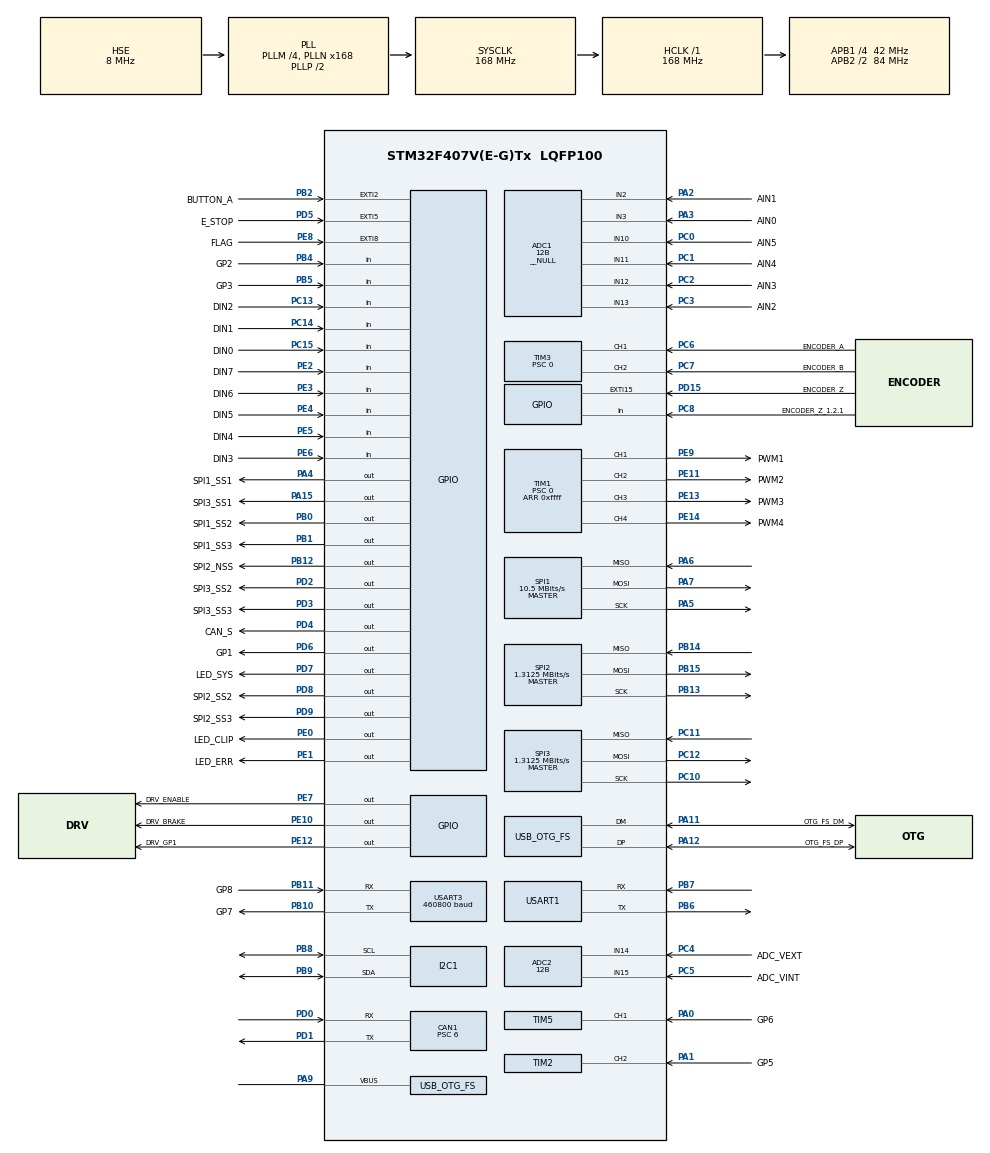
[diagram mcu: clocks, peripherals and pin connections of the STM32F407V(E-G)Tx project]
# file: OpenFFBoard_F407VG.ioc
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ADC1.Channel-1\#ChannelRegularConversion=ADC_CHANNEL_3
ADC1.Channel-2\#ChannelRegularConversion=ADC_CHANNEL_2
ADC1.Channel-3\#ChannelRegularConversion=ADC_CHANNEL_13
ADC1.Channel-4\#ChannelRegularConversion=ADC_CHANNEL_12
ADC1.Channel-5\#ChannelRegularConversion=ADC_CHANNEL_11
ADC1.Channel-6\#ChannelRegularConversion=ADC_CHANNEL_10
ADC1.Channel-7\#ChannelRegularConversion=ADC_CHANNEL_TEMPSENSOR
ADC1.Channel-9\#ChannelRegularConversion=ADC_CHANNEL_VREFINT
ADC1.Channel-IN10=ADC_CHANNEL_10
ADC1.Channel-IN11=ADC_CHANNEL_11
ADC1.Channel-IN12=ADC_CHANNEL_12
ADC1.Channel-IN13=ADC_CHANNEL_13
ADC1.ClockPrescaler=ADC_CLOCK_SYNC_PCLK_DIV4
ADC1.ContinuousConvMode=DISABLE
ADC1.DMAContinuousRequests=ENABLE
ADC1.DataAlign=ADC_DATAALIGN_RIGHT
ADC1.DiscontinuousConvMode=DISABLE
ADC1.EOCSelection=ADC_EOC_SINGLE_CONV
ADC1.EnableAnalogWatchDog=false
ADC1.ExternalTrigConv=ADC_EXTERNALTRIGCONV_T4_CC4
ADC1.ExternalTrigConvEdge=ADC_EXTERNALTRIGCONVEDGE_RISING
ADC1.InjNumberOfConversion=0
ADC1.Mode=__NULL
ADC1.NbrOfConversion=8
ADC1.Rank-1\#ChannelRegularConversion=1
ADC1.Rank-2\#ChannelRegularConversion=2
ADC1.Rank-3\#ChannelRegularConversion=3
ADC1.Rank-4\#ChannelRegularConversion=4
ADC1.Rank-5\#ChannelRegularConversion=5
ADC1.Rank-6\#ChannelRegularConversion=6
ADC1.Rank-7\#ChannelRegularConversion=7
ADC1.Rank-9\#ChannelRegularConversion=8
ADC1.Resolution=ADC_RESOLUTION_12B
ADC1.SamplingTime-1\#ChannelRegularConversion=ADC_SAMPLETIME_84CYCLES
ADC1.SamplingTime-2\#ChannelRegularConversion=ADC_SAMPLETIME_84CYCLES
ADC1.SamplingTime-3\#ChannelRegularConversion=ADC_SAMPLETIME_84CYCLES
ADC1.SamplingTime-4\#ChannelRegularConversion=ADC_SAMPLETIME_84CYCLES
ADC1.SamplingTime-5\#ChannelRegularConversion=ADC_SAMPLETIME_84CYCLES
ADC1.SamplingTime-6\#ChannelRegularConversion=ADC_SAMPLETIME_84CYCLES
ADC1.SamplingTime-7\#ChannelRegularConversion=ADC_SAMPLETIME_56CYCLES
ADC1.SamplingTime-9\#ChannelRegularConversion=ADC_SAMPLETIME_56CYCLES
ADC1.master=1
ADC2.Channel-0\#ChannelRegularConversion=ADC_CHANNEL_14
ADC2.Channel-1\#ChannelRegularConversion=ADC_CHANNEL_15
ADC2.ClockPrescaler=ADC_CLOCK_SYNC_PCLK_DIV4
ADC2.ContinuousConvMode=DISABLE
ADC2.DMAContinuousRequests=ENABLE
ADC2.DataAlign=ADC_DATAALIGN_RIGHT
ADC2.DiscontinuousConvMode=DISABLE
ADC2.EOCSelection=ADC_EOC_SINGLE_CONV
ADC2.EnableAnalogWatchDog=false
ADC2.ExternalTrigConv=ADC_EXTERNALTRIGCONV_T4_CC4
ADC2.ExternalTrigConvEdge=ADC_EXTERNALTRIGCONVEDGE_RISINGFALLING
ADC2.InjNumberOfConversion=0
ADC2.Mode=__NULL
ADC2.NbrOfConversion=2
ADC2.Rank-0\#ChannelRegularConversion=1
ADC2.Rank-1\#ChannelRegularConversion=2
ADC2.Resolution=ADC_RESOLUTION_12B
ADC2.SamplingTime-0\#ChannelRegularConversion=ADC_SAMPLETIME_84CYCLES
ADC2.SamplingTime-1\#ChannelRegularConversion=ADC_SAMPLETIME_84CYCLES
ADC2.ScanConvMode=ENABLE
CAN1.ABOM=DISABLE
CAN1.AWUM=DISABLE
CAN1.BS1=CAN_BS1_11TQ
CAN1.BS2=CAN_BS2_2TQ
CAN1.CalculateBaudRate=500000
CAN1.CalculateTimeBit=2000
CAN1.CalculateTimeQuantum=142.85714285714286
CAN1.Mode=CAN_MODE_NORMAL
CAN1.NART=ENABLE
CAN1.Prescaler=6
CAN1.RFLM=DISABLE
CAN1.SJW=CAN_SJW_1TQ
CAN1.TTCM=DISABLE
CAN1.TXFP=DISABLE
Dma.ADC1.0.Direction=DMA_PERIPH_TO_MEMORY
Dma.ADC1.0.FIFOMode=DMA_FIFOMODE_DISABLE
Dma.ADC1.0.Instance=DMA2_Stream4
Dma.ADC1.0.MemDataAlignment=DMA_MDATAALIGN_WORD
Dma.ADC1.0.MemInc=DMA_MINC_ENABLE
Dma.ADC1.0.Mode=DMA_CIRCULAR
Dma.ADC1.0.PeriphDataAlignment=DMA_PDATAALIGN_WORD
Dma.ADC1.0.PeriphInc=DMA_PINC_DISABLE
Dma.ADC1.0.Priority=DMA_PRIORITY_LOW
Dma.ADC2.1.Direction=DMA_PERIPH_TO_MEMORY
Dma.ADC2.1.FIFOMode=DMA_FIFOMODE_DISABLE
Dma.ADC2.1.Instance=DMA2_Stream2
Dma.ADC2.1.MemDataAlignment=DMA_MDATAALIGN_WORD
Dma.ADC2.1.MemInc=DMA_MINC_ENABLE
Dma.ADC2.1.Mode=DMA_CIRCULAR
Dma.ADC2.1.PeriphDataAlignment=DMA_PDATAALIGN_WORD
Dma.ADC2.1.PeriphInc=DMA_PINC_DISABLE
Dma.ADC2.1.Priority=DMA_PRIORITY_LOW
Dma.Request0=ADC1
Dma.Request1=ADC2
Dma.Request2=SPI1_RX
Dma.Request3=SPI1_TX
Dma.Request4=SPI3_RX
Dma.Request5=SPI3_TX
Dma.Request6=SPI2_RX
Dma.Request7=SPI2_TX
Dma.SPI1_RX.2.Direction=DMA_PERIPH_TO_MEMORY
Dma.SPI1_RX.2.FIFOMode=DMA_FIFOMODE_DISABLE
Dma.SPI1_RX.2.Instance=DMA2_Stream0
Dma.SPI1_RX.2.MemDataAlignment=DMA_MDATAALIGN_BYTE
Dma.SPI1_RX.2.MemInc=DMA_MINC_ENABLE
Dma.SPI1_RX.2.Mode=DMA_NORMAL
Dma.SPI1_RX.2.PeriphDataAlignment=DMA_PDATAALIGN_BYTE
Dma.SPI1_RX.2.PeriphInc=DMA_PINC_DISABLE
Dma.SPI1_RX.2.Priority=DMA_PRIORITY_MEDIUM
Dma.SPI1_TX.3.Direction=DMA_MEMORY_TO_PERIPH
Dma.SPI1_TX.3.FIFOMode=DMA_FIFOMODE_DISABLE
Dma.SPI1_TX.3.Instance=DMA2_Stream3
Dma.SPI1_TX.3.MemDataAlignment=DMA_MDATAALIGN_BYTE
Dma.SPI1_TX.3.MemInc=DMA_MINC_ENABLE
Dma.SPI1_TX.3.Mode=DMA_NORMAL
Dma.SPI1_TX.3.PeriphDataAlignment=DMA_PDATAALIGN_BYTE
Dma.SPI1_TX.3.PeriphInc=DMA_PINC_DISABLE
Dma.SPI1_TX.3.Priority=DMA_PRIORITY_MEDIUM
Dma.SPI2_RX.6.Direction=DMA_PERIPH_TO_MEMORY
Dma.SPI2_RX.6.FIFOMode=DMA_FIFOMODE_DISABLE
Dma.SPI2_RX.6.Instance=DMA1_Stream3
Dma.SPI2_RX.6.MemDataAlignment=DMA_MDATAALIGN_BYTE
Dma.SPI2_RX.6.MemInc=DMA_MINC_ENABLE
Dma.SPI2_RX.6.Mode=DMA_NORMAL
Dma.SPI2_RX.6.PeriphDataAlignment=DMA_PDATAALIGN_BYTE
Dma.SPI2_RX.6.PeriphInc=DMA_PINC_DISABLE
Dma.SPI2_RX.6.Priority=DMA_PRIORITY_LOW
Dma.SPI2_TX.7.Direction=DMA_MEMORY_TO_PERIPH
Dma.SPI2_TX.7.FIFOMode=DMA_FIFOMODE_DISABLE
Dma.SPI2_TX.7.Instance=DMA1_Stream4
Dma.SPI2_TX.7.MemDataAlignment=DMA_MDATAALIGN_BYTE
Dma.SPI2_TX.7.MemInc=DMA_MINC_ENABLE
Dma.SPI2_TX.7.Mode=DMA_NORMAL
Dma.SPI2_TX.7.PeriphDataAlignment=DMA_PDATAALIGN_BYTE
Dma.SPI2_TX.7.PeriphInc=DMA_PINC_DISABLE
Dma.SPI2_TX.7.Priority=DMA_PRIORITY_LOW
Dma.SPI3_RX.4.Direction=DMA_PERIPH_TO_MEMORY
Dma.SPI3_RX.4.FIFOMode=DMA_FIFOMODE_DISABLE
Dma.SPI3_RX.4.Instance=DMA1_Stream2
Dma.SPI3_RX.4.MemDataAlignment=DMA_MDATAALIGN_BYTE
Dma.SPI3_RX.4.MemInc=DMA_MINC_ENABLE
Dma.SPI3_RX.4.Mode=DMA_NORMAL
Dma.SPI3_RX.4.PeriphDataAlignment=DMA_PDATAALIGN_BYTE
Dma.SPI3_RX.4.PeriphInc=DMA_PINC_DISABLE
Dma.SPI3_RX.4.Priority=DMA_PRIORITY_MEDIUM
Dma.SPI3_TX.5.Direction=DMA_MEMORY_TO_PERIPH
Dma.SPI3_TX.5.FIFOMode=DMA_FIFOMODE_DISABLE
Dma.SPI3_TX.5.Instance=DMA1_Stream5
Dma.SPI3_TX.5.MemDataAlignment=DMA_MDATAALIGN_BYTE
Dma.SPI3_TX.5.MemInc=DMA_MINC_ENABLE
Dma.SPI3_TX.5.Mode=DMA_NORMAL
Dma.SPI3_TX.5.PeriphDataAlignment=DMA_PDATAALIGN_BYTE
Dma.SPI3_TX.5.PeriphInc=DMA_PINC_DISABLE
Dma.SPI3_TX.5.Priority=DMA_PRIORITY_MEDIUM
FREERTOS.HEAP_NUMBER=4
FREERTOS.Tasks01=defaultTask,16,512,StartDefaultTask,As weak,NULL,Dynamic,NULL,NULL
FREERTOS.configCHECK_FOR_STACK_OVERFLOW=2
FREERTOS.configENABLE_FPU=1
FREERTOS.configGENERATE_RUN_TIME_STATS=0
FREERTOS.configMINIMAL_STACK_SIZE=64
FREERTOS.configRECORD_STACK_HIGH_ADDRESS=1
FREERTOS.configTIMER_TASK_STACK_DEPTH=128
FREERTOS.configTOTAL_HEAP_SIZE=0xffff
FREERTOS.configUSE_IDLE_HOOK=1
FREERTOS.configUSE_MALLOC_FAILED_HOOK=1
FREERTOS.configUSE_NEWLIB_REENTRANT=1
FREERTOS.configUSE_STATS_FORMATTING_FUNCTIONS=0
FREERTOS.configUSE_TRACE_FACILITY=1
IWDG.Prescaler=IWDG_PRESCALER_16
Mcu.Family=STM32F4
Mcu.Name=STM32F407V(E-G)Tx
Mcu.Package=LQFP100
NVIC.CAN1_RX0_IRQn=true\:9\:0\:true\:false\:true\:true\:true\:true\:true
NVIC.CAN1_TX_IRQn=true\:10\:0\:true\:false\:true\:true\:true\:true\:true
NVIC.DMA1_Stream2_IRQn=true\:5\:0\:false\:false\:true\:true\:false\:true\:true
NVIC.DMA1_Stream3_IRQn=true\:9\:0\:true\:false\:true\:true\:false\:true\:true
NVIC.DMA1_Stream4_IRQn=true\:9\:0\:true\:false\:true\:true\:false\:true\:true
NVIC.DMA1_Stream5_IRQn=true\:5\:0\:true\:false\:true\:true\:false\:true\:true
NVIC.DMA2_Stream0_IRQn=true\:6\:0\:true\:true\:true\:1\:true\:false\:true\:true
NVIC.DMA2_Stream2_IRQn=true\:10\:0\:true\:false\:true\:true\:false\:true\:true
NVIC.DMA2_Stream3_IRQn=true\:6\:0\:true\:false\:true\:true\:false\:true\:true
NVIC.DMA2_Stream4_IRQn=true\:10\:0\:true\:false\:true\:true\:false\:true\:true
NVIC.EXTI15_10_IRQn=true\:13\:0\:true\:false\:true\:true\:true\:true\:true
NVIC.EXTI2_IRQn=true\:6\:0\:true\:false\:true\:true\:true\:true\:true
NVIC.EXTI9_5_IRQn=true\:13\:0\:true\:false\:true\:true\:true\:true\:true
NVIC.I2C1_ER_IRQn=true\:8\:0\:true\:false\:true\:true\:true\:true\:true
NVIC.I2C1_EV_IRQn=true\:8\:0\:true\:false\:true\:true\:true\:true\:true
NVIC.OTG_FS_IRQn=true\:14\:0\:true\:false\:true\:true\:true\:false\:true
NVIC.PriorityGroup=NVIC_PRIORITYGROUP_4
NVIC.SPI1_IRQn=true\:6\:0\:true\:false\:true\:true\:true\:true\:true
NVIC.SPI2_IRQn=true\:9\:0\:true\:false\:true\:true\:true\:true\:true
NVIC.SPI3_IRQn=true\:8\:0\:true\:false\:true\:true\:true\:true\:true
NVIC.TIM1_BRK_TIM9_IRQn=true\:6\:0\:true\:false\:true\:true\:true\:true\:true
NVIC.TIM2_IRQn=true\:7\:0\:true\:false\:true\:true\:true\:true\:true
NVIC.TIM3_IRQn=true\:6\:0\:true\:true\:true\:2\:true\:true\:true\:true
NVIC.TIM5_IRQn=true\:6\:0\:true\:false\:true\:true\:true\:true\:true
NVIC.TIM6_DAC_IRQn=true\:11\:0\:true\:false\:true\:true\:true\:true\:true
NVIC.TIM7_IRQn=true\:4\:0\:true\:false\:true\:false\:false\:true\:true
NVIC.TIM8_UP_TIM13_IRQn=true\:12\:0\:true\:false\:true\:false\:true\:true\:true
NVIC.TimeBase=TIM7_IRQn
NVIC.TimeBaseIP=TIM7
NVIC.USART1_IRQn=true\:7\:0\:true\:false\:true\:true\:true\:true\:true
NVIC.USART3_IRQn=true\:7\:0\:true\:false\:true\:true\:true\:true\:true
PA0-WKUP.GPIO_Label=GP6
PA0-WKUP.Signal=S_TIM5_CH1
PA1.GPIO_Label=GP5
PA1.Signal=S_TIM2_CH2
PA11.GPIO_Label=OTG_FS_DM
PA11.Mode=Device_Only
PA11.Signal=USB_OTG_FS_DM
PA12.GPIO_Label=OTG_FS_DP
PA12.Mode=Device_Only
PA12.Signal=USB_OTG_FS_DP
PA13.GPIO_Label=SWDIO
PA13.Mode=Trace_Asynchronous_SW
PA13.Signal=SYS_JTMS-SWDIO
PA14.GPIO_Label=SWCLK
PA14.Mode=Trace_Asynchronous_SW
PA14.Signal=SYS_JTCK-SWCLK
PA15.GPIO_Label=SPI3_SS1
PA15.GPIO_Speed=GPIO_SPEED_FREQ_HIGH
PA15.Signal=GPIO_Output
PA2.GPIO_Label=AIN1
PA2.Signal=ADCx_IN2
PA3.GPIO_Label=AIN0
PA3.Signal=ADCx_IN3
PA4.GPIO_Label=SPI1_SS1
PA4.GPIO_Speed=GPIO_SPEED_FREQ_VERY_HIGH
PA4.PinState=GPIO_PIN_SET
PA4.Signal=GPIO_Output
PA5.Mode=Full_Duplex_Master
PA5.Signal=SPI1_SCK
PA6.GPIO_PuPd=GPIO_NOPULL
PA6.Mode=Full_Duplex_Master
PA6.Signal=SPI1_MISO
PA7.Mode=Full_Duplex_Master
PA7.Signal=SPI1_MOSI
PA9.Mode=Activate_VBUS
PA9.Signal=USB_OTG_FS_VBUS
PB0.GPIO_Label=SPI1_SS2
PB0.GPIO_Speed=GPIO_SPEED_FREQ_HIGH
PB0.Signal=GPIO_Output
PB1.GPIO_Label=SPI1_SS3
PB1.GPIO_Speed=GPIO_SPEED_FREQ_HIGH
PB1.Signal=GPIO_Output
PB10.GPIO_Label=GP7
PB10.Mode=Asynchronous
PB10.Signal=USART3_TX
PB11.GPIO_Label=GP8
PB11.Mode=Asynchronous
PB11.Signal=USART3_RX
PB12.GPIO_Label=SPI2_NSS
PB12.GPIO_Speed=GPIO_SPEED_FREQ_HIGH
PB12.Signal=GPIO_Output
PB13.Mode=Full_Duplex_Master
PB13.Signal=SPI2_SCK
PB14.Mode=Full_Duplex_Master
PB14.Signal=SPI2_MISO
PB15.Mode=Full_Duplex_Master
PB15.Signal=SPI2_MOSI
PB2.GPIO_Label=BUTTON_A
PB2.GPIO_PuPd=GPIO_PULLDOWN
PB2.Signal=GPXTI2
PB3.GPIO_Label=GP4
PB3.Mode=Trace_Asynchronous_SW
PB3.Signal=SYS_JTDO-SWO
PB4.GPIO_Label=GP2
PB4.Signal=GPIO_Input
PB5.GPIO_Label=GP3
PB5.Signal=GPIO_Input
PB6.Mode=Asynchronous
PB6.Signal=USART1_TX
PB7.Mode=Asynchronous
PB7.Signal=USART1_RX
PB8.GPIO_Pu=GPIO_PULLUP
PB8.Mode=I2C
PB8.Signal=I2C1_SCL
PB9.GPIO_Pu=GPIO_PULLUP
PB9.Mode=I2C
PB9.Signal=I2C1_SDA
PC0.GPIO_Label=AIN5
PC0.Signal=ADCx_IN10
PC1.GPIO_Label=AIN4
PC1.Signal=ADCx_IN11
PC10.Mode=Full_Duplex_Master
PC10.Signal=SPI3_SCK
PC11.Mode=Full_Duplex_Master
PC11.Signal=SPI3_MISO
PC12.Mode=Full_Duplex_Master
PC12.Signal=SPI3_MOSI
PC13-ANTI_TAMP.GPIO_Label=DIN2
PC13-ANTI_TAMP.GPIO_PuPd=GPIO_PULLUP
PC13-ANTI_TAMP.Signal=GPIO_Input
PC14-OSC32_IN.GPIO_Label=DIN1
PC14-OSC32_IN.GPIO_PuPd=GPIO_PULLUP
PC14-OSC32_IN.Signal=GPIO_Input
PC15-OSC32_OUT.GPIO_Label=DIN0
PC15-OSC32_OUT.GPIO_PuPd=GPIO_PULLUP
PC15-OSC32_OUT.Signal=GPIO_Input
PC2.GPIO_Label=AIN3
PC2.Signal=ADCx_IN12
PC3.GPIO_Label=AIN2
PC3.Signal=ADCx_IN13
PC4.GPIO_Label=ADC_VEXT
PC4.Signal=ADCx_IN14
PC5.GPIO_Label=ADC_VINT
PC5.Signal=ADCx_IN15
PC6.GPIO_Label=ENCODER_A
PC6.GPIO_PuPd=GPIO_NOPULL
PC6.Signal=S_TIM3_CH1
PC7.GPIO_Label=ENCODER_B
PC7.GPIO_PuPd=GPIO_NOPULL
PC7.Signal=S_TIM3_CH2
PC8.GPIO_Label=ENCODER_Z_1.2.1
PC8.GPIO_PuPd=GPIO_NOPULL
PC8.Signal=GPIO_Input
PD0.Mode=CAN_Activate
PD0.Signal=CAN1_RX
PD1.Mode=CAN_Activate
PD1.Signal=CAN1_TX
PD15.GPIO_Label=ENCODER_Z
PD15.GPIO_ModeDefaultEXTI=GPIO_MODE_IT_FALLING
PD15.Signal=GPXTI15
PD2.GPIO_Label=SPI3_SS2
PD2.GPIO_Speed=GPIO_SPEED_FREQ_MEDIUM
PD2.Signal=GPIO_Output
PD3.GPIO_Label=SPI3_SS3
PD3.GPIO_Speed=GPIO_SPEED_FREQ_MEDIUM
PD3.Signal=GPIO_Output
PD4.GPIO_Label=CAN_S
PD4.GPIO_PuPd=GPIO_NOPULL
PD4.PinState=GPIO_PIN_RESET
PD4.Signal=GPIO_Output
PD5.GPIO_Label=E_STOP
PD5.GPIO_ModeDefaultEXTI=GPIO_MODE_IT_RISING_FALLING
PD5.GPIO_PuPd=GPIO_PULLUP
PD5.Signal=GPXTI5
PD6.GPIO_Label=GP1
PD6.Signal=GPIO_Output
PD7.GPIO_Label=LED_SYS
PD7.Signal=GPIO_Output
PD8.GPIO_Label=SPI2_SS2
PD8.GPIO_Speed=GPIO_SPEED_FREQ_MEDIUM
PD8.Signal=GPIO_Output
PD9.GPIO_Label=SPI2_SS3
PD9.GPIO_Speed=GPIO_SPEED_FREQ_MEDIUM
PD9.Signal=GPIO_Output
PE0.GPIO_Label=LED_CLIP
PE0.Signal=GPIO_Output
PE1.GPIO_Label=LED_ERR
PE1.Signal=GPIO_Output
PE10.GPIO_Label=DRV_BRAKE
PE10.GPIO_PuPd=GPIO_PULLDOWN
PE10.GPIO_Speed=GPIO_SPEED_FREQ_MEDIUM
PE10.Signal=GPIO_Output
PE11.GPIO_Label=PWM2
PE11.GPIO_Speed=GPIO_SPEED_FREQ_HIGH
PE11.Signal=S_TIM1_CH2
PE12.GPIO_Label=DRV_GP1
PE12.Signal=GPIO_Output
PE13.GPIO_Label=PWM3
PE13.GPIO_Speed=GPIO_SPEED_FREQ_HIGH
PE13.Signal=S_TIM1_CH3
PE14.GPIO_Label=PWM4
PE14.GPIO_Speed=GPIO_SPEED_FREQ_HIGH
PE14.Signal=S_TIM1_CH4
PE2.GPIO_Label=DIN7
PE2.GPIO_PuPd=GPIO_PULLUP
PE2.Signal=GPIO_Input
PE3.GPIO_Label=DIN6
PE3.GPIO_PuPd=GPIO_PULLUP
PE3.Signal=GPIO_Input
PE4.GPIO_Label=DIN5
PE4.GPIO_PuPd=GPIO_PULLUP
PE4.Signal=GPIO_Input
PE5.GPIO_Label=DIN4
PE5.GPIO_PuPd=GPIO_PULLUP
PE5.Signal=GPIO_Input
PE6.GPIO_Label=DIN3
PE6.GPIO_PuPd=GPIO_PULLUP
PE6.Signal=GPIO_Input
PE7.GPIO_Label=DRV_ENABLE
PE7.GPIO_PuPd=GPIO_PULLDOWN
PE7.Signal=GPIO_Output
PE8.GPIO_Label=FLAG
PE8.GPIO_PuPd=GPIO_PULLDOWN
PE8.Signal=GPXTI8
PE9.GPIO_Label=PWM1
PE9.GPIO_PuPd=GPIO_NOPULL
PE9.GPIO_Speed=GPIO_SPEED_FREQ_HIGH
PE9.Signal=S_TIM1_CH1
PH0-OSC_IN.Mode=HSE-External-Oscillator
PH0-OSC_IN.Signal=RCC_OSC_IN
PH1-OSC_OUT.Mode=HSE-External-Oscillator
PH1-OSC_OUT.Signal=RCC_OSC_OUT
ProjectManager.HeapSize=0x400
ProjectManager.StackSize=0x400
ProjectManager.TargetToolchain=STM32CubeIDE
RCC.48MHZClocksFreq_Value=48000000
RCC.AHBFreq_Value=168000000
RCC.APB1CLKDivider=RCC_HCLK_DIV4
RCC.APB1Freq_Value=42000000
RCC.APB1TimFreq_Value=84000000
RCC.APB2CLKDivider=RCC_HCLK_DIV2
RCC.APB2Freq_Value=84000000
RCC.APB2TimFreq_Value=168000000
RCC.CortexFreq_Value=168000000
RCC.HCLKFreq_Value=168000000
RCC.HSE_VALUE=8000000
RCC.HSI_VALUE=16000000
RCC.LSE_VALUE=32768
RCC.PLLM=4
RCC.PLLN=168
RCC.PLLQ=7
RCC.RCC_MCO1Source=RCC_MCO1SOURCE_PLLCLK
RCC.SYSCLKFreq_VALUE=168000000
RCC.SYSCLKSource=RCC_SYSCLKSOURCE_PLLCLK
RCC.VCOOutputFreq_Value=336000000
SH.ADCx_IN10.0=ADC1_IN10,IN10
SH.ADCx_IN11.0=ADC1_IN11,IN11
SH.ADCx_IN12.0=ADC1_IN12,IN12
SH.ADCx_IN13.0=ADC1_IN13,IN13
SH.ADCx_IN14.0=ADC2_IN14,IN14
SH.ADCx_IN15.0=ADC2_IN15,IN15
SH.ADCx_IN2.0=ADC1_IN2,IN2
SH.ADCx_IN3.0=ADC1_IN3,IN3
SH.S_TIM1_CH1.0=TIM1_CH1,PWM Generation1 CH1
SH.S_TIM1_CH2.0=TIM1_CH2,PWM Generation2 CH2
SH.S_TIM1_CH3.0=TIM1_CH3,PWM Generation3 CH3
SH.S_TIM1_CH4.0=TIM1_CH4,PWM Generation4 CH4
SH.S_TIM2_CH2.0=TIM2_CH2,PWM_Input_2
SH.S_TIM3_CH1.0=TIM3_CH1,Encoder_Interface
SH.S_TIM3_CH2.0=TIM3_CH2,Encoder_Interface
SH.S_TIM5_CH1.0=TIM5_CH1,PWM_Input_1
SPI1.BaudRatePrescaler=SPI_BAUDRATEPRESCALER_8
SPI1.CLKPhase=SPI_PHASE_2EDGE
SPI1.CLKPolarity=SPI_POLARITY_HIGH
SPI1.CRCCalculation=SPI_CRCCALCULATION_DISABLE
SPI1.CalculateBaudRate=10.5 MBits/s
SPI1.DataSize=SPI_DATASIZE_8BIT
SPI1.Direction=SPI_DIRECTION_2LINES
SPI1.FirstBit=SPI_FIRSTBIT_MSB
SPI1.Mode=SPI_MODE_MASTER
SPI1.NSS=SPI_NSS_SOFT
SPI1.TIMode=SPI_TIMODE_DISABLE
SPI1.VirtualType=VM_MASTER
SPI2.BaudRatePrescaler=SPI_BAUDRATEPRESCALER_32
SPI2.CLKPhase=SPI_PHASE_1EDGE
SPI2.CLKPolarity=SPI_POLARITY_LOW
SPI2.CRCCalculation=SPI_CRCCALCULATION_DISABLE
SPI2.CalculateBaudRate=1.3125 MBits/s
SPI2.Direction=SPI_DIRECTION_2LINES
SPI2.FirstBit=SPI_FIRSTBIT_MSB
SPI2.Mode=SPI_MODE_MASTER
SPI2.NSS=SPI_NSS_SOFT
SPI2.TIMode=SPI_TIMODE_DISABLE
SPI2.VirtualType=VM_MASTER
SPI3.BaudRatePrescaler=SPI_BAUDRATEPRESCALER_32
SPI3.CLKPhase=SPI_PHASE_1EDGE
SPI3.CLKPolarity=SPI_POLARITY_LOW
SPI3.CRCCalculation=SPI_CRCCALCULATION_DISABLE
SPI3.CalculateBaudRate=1.3125 MBits/s
SPI3.Direction=SPI_DIRECTION_2LINES
SPI3.FirstBit=SPI_FIRSTBIT_MSB
SPI3.Mode=SPI_MODE_MASTER
SPI3.NSS=SPI_NSS_SOFT
SPI3.TIMode=SPI_TIMODE_DISABLE
SPI3.VirtualType=VM_MASTER
TIM1.AutoReloadPreload=TIM_AUTORELOAD_PRELOAD_ENABLE
TIM1.Channel-PWM\ Generation1\ CH1=TIM_CHANNEL_1
TIM1.Channel-PWM\ Generation2\ CH2=TIM_CHANNEL_2
TIM1.Channel-PWM\ Generation3\ CH3=TIM_CHANNEL_3
TIM1.Channel-PWM\ Generation4\ CH4=TIM_CHANNEL_4
TIM1.ClockDivision=TIM_CLOCKDIVISION_DIV1
TIM1.CounterMode=TIM_COUNTERMODE_UP
TIM1.Period=0xffff
TIM1.Prescaler=0
TIM1.RepetitionCounter=0
TIM1.TIM_MasterOutputTrigger=TIM_TRGO_RESET
TIM1.TIM_MasterSlaveMode=TIM_MASTERSLAVEMODE_DISABLE
TIM13.Period=100
TIM13.Prescaler=167
TIM2.AutoReloadPreload=TIM_AUTORELOAD_PRELOAD_DISABLE
TIM2.ClockDivision=TIM_CLOCKDIVISION_DIV1
TIM2.CounterMode=TIM_COUNTERMODE_UP
TIM2.Period=0xffffffff
TIM2.Prescaler=0
TIM2.TIM_MasterOutputTrigger=TIM_TRGO_RESET
TIM2.TIM_MasterSlaveMode=TIM_MASTERSLAVEMODE_DISABLE
TIM3.AutoReloadPreload=TIM_AUTORELOAD_PRELOAD_DISABLE
TIM3.ClockDivision=TIM_CLOCKDIVISION_DIV1
TIM3.CounterMode=TIM_COUNTERMODE_CENTERALIGNED1
TIM3.EncoderMode=TIM_ENCODERMODE_TI12
TIM3.IC1Filter=0
TIM3.IC1Polarity=TIM_ICPOLARITY_FALLING
TIM3.IC1Prescaler=TIM_ICPSC_DIV1
TIM3.IC1Selection=TIM_ICSELECTION_DIRECTTI
TIM3.IC2Filter=0
TIM3.IC2Polarity=TIM_ICPOLARITY_FALLING
TIM3.IC2Prescaler=TIM_ICPSC_DIV1
TIM3.IC2Selection=TIM_ICSELECTION_DIRECTTI
TIM3.Period=0xffff
TIM3.Prescaler=0
TIM3.TIM_MasterOutputTrigger=TIM_TRGO_RESET
TIM3.TIM_MasterSlaveMode=TIM_MASTERSLAVEMODE_DISABLE
TIM4.AutoReloadPreload=TIM_AUTORELOAD_PRELOAD_DISABLE
TIM4.Channel-PWM\ Generation4\ No\ Output=TIM_CHANNEL_4
TIM4.ClockDivision=TIM_CLOCKDIVISION_DIV1
TIM4.CounterMode=TIM_COUNTERMODE_UP
TIM4.Period=100
TIM4.Prescaler=84-1
TIM4.Pulse-PWM\ Generation4\ No\ Output=50
TIM4.TIM_MasterOutputTrigger=TIM_TRGO_RESET
TIM4.TIM_MasterSlaveMode=TIM_MASTERSLAVEMODE_DISABLE
TIM5.AutoReloadPreload=TIM_AUTORELOAD_PRELOAD_DISABLE
TIM5.ClockDivision=TIM_CLOCKDIVISION_DIV1
TIM5.CounterMode=TIM_COUNTERMODE_UP
TIM5.Period=0xffffffff
TIM5.Prescaler=0
TIM5.TIM_MasterOutputTrigger=TIM_TRGO_RESET
TIM5.TIM_MasterSlaveMode=TIM_MASTERSLAVEMODE_DISABLE
TIM6.Prescaler=167
TIM8.Channel-Output\ Compare1\ No\ Output=TIM_CHANNEL_1
TIM8.TIM_MasterOutputTrigger=TIM_TRGO_OC1REF
USART1.VirtualMode=VM_ASYNC
USART3.BaudRate=460800
USART3.VirtualMode=VM_ASYNC
USB_OTG_FS.Sof_enable=DISABLE
USB_OTG_FS.VirtualMode=Device_Only
USB_OTG_FS.low_power_enable=DISABLE
USB_OTG_FS.lpm_enable=DISABLE
USB_OTG_FS.vbus_sensing_enable=ENABLE
VP_ADC1_TempSens_Input.Mode=IN-TempSens
VP_ADC1_Vref_Input.Mode=IN-Vrefint
VP_FREERTOS_VS_CMSIS_V2.Mode=CMSIS_V2
VP_IWDG_VS_IWDG.Mode=IWDG_Activate
VP_SYS_VS_tim7.Mode=TIM7
VP_TIM13_VS_ClockSourceINT.Mode=Enable_Timer
VP_TIM1_VS_ClockSourceINT.Mode=Internal
VP_TIM2_VS_ClockSourceINT.Mode=Internal
VP_TIM4_VS_ClockSourceINT.Mode=Internal
VP_TIM4_VS_no_output4.Mode=PWM Generation4 No Output
VP_TIM5_VS_ClockSourceINT.Mode=Internal
VP_TIM6_VS_ClockSourceINT.Mode=Enable_Timer
VP_TIM8_VS_ClockSourceINT.Mode=Internal
VP_TIM8_VS_no_output1.Mode=Output Compare1 No Output
VP_TIM9_VS_ClockSourceINT.Mode=Internal
board=custom

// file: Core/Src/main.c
/* USER CODE BEGIN Header */
/**
  ******************************************************************************
  * @file           : main.c
  * @brief          : Main program body
  ******************************************************************************
  * @attention
  *
  * <h2><center>&copy; Copyright (c) 2020 STMicroelectronics.
  * All rights reserved.</center></h2>
  *
  * This software component is licensed by ST under BSD 3-Clause license,
  * the "License"; You may not use this file except in compliance with the
  * License. You may obtain a copy of the License at:
  *                        opensource.org/licenses/BSD-3-Clause
  *
  ******************************************************************************
  */
/* USER CODE END Header */
#include "main.h"
#include "cmsis_os.h"

/* USER CODE BEGIN Includes */
#include "global_callbacks.h"
#include "cppmain.h"
extern void cppmain();
/* USER CODE END Includes */

ADC_HandleTypeDef hadc1;
ADC_HandleTypeDef hadc2;
DMA_HandleTypeDef hdma_adc1;
DMA_HandleTypeDef hdma_adc2;

CAN_HandleTypeDef hcan1;

I2C_HandleTypeDef hi2c1;

IWDG_HandleTypeDef hiwdg;

SPI_HandleTypeDef hspi1;
SPI_HandleTypeDef hspi2;
SPI_HandleTypeDef hspi3;
DMA_HandleTypeDef hdma_spi1_rx;
DMA_HandleTypeDef hdma_spi1_tx;
DMA_HandleTypeDef hdma_spi2_rx;
DMA_HandleTypeDef hdma_spi2_tx;
DMA_HandleTypeDef hdma_spi3_rx;
DMA_HandleTypeDef hdma_spi3_tx;

TIM_HandleTypeDef htim1;
TIM_HandleTypeDef htim2;
TIM_HandleTypeDef htim3;
TIM_HandleTypeDef htim4;
TIM_HandleTypeDef htim5;
TIM_HandleTypeDef htim6;
TIM_HandleTypeDef htim8;
TIM_HandleTypeDef htim9;
TIM_HandleTypeDef htim13;

UART_HandleTypeDef huart1;
UART_HandleTypeDef huart3;

PCD_HandleTypeDef hpcd_USB_OTG_FS;

/* Definitions for defaultTask */
osThreadId_t defaultTaskHandle;
const osThreadAttr_t defaultTask_attributes = {
  .name = "defaultTask",
  .stack_size = 512 * 4,
  .priority = (osPriority_t) osPriorityBelowNormal,
};
/* USER CODE BEGIN PV */
// dummy main
__attribute__((weak)) void cppmain(){
	Error_Handler();
}
/* USER CODE END PV */

void SystemClock_Config(void);
static void MX_GPIO_Init(void);
static void MX_DMA_Init(void);
static void MX_TIM3_Init(void);
static void MX_ADC1_Init(void);
static void MX_TIM2_Init(void);
static void MX_TIM1_Init(void);
static void MX_SPI2_Init(void);
static void MX_TIM4_Init(void);
static void MX_TIM5_Init(void);
static void MX_SPI1_Init(void);
static void MX_CAN1_Init(void);
static void MX_ADC2_Init(void);
static void MX_I2C1_Init(void);
static void MX_SPI3_Init(void);
static void MX_USART1_UART_Init(void);
static void MX_TIM9_Init(void);
static void MX_IWDG_Init(void);
static void MX_USART3_UART_Init(void);
static void MX_TIM13_Init(void);
static void MX_TIM6_Init(void);
static void MX_TIM8_Init(void);
void StartDefaultTask(void *argument);

static void MX_NVIC_Init(void);

int main(void)
{

  /* MCU Configuration--------------------------------------------------------*/

  /* Reset of all peripherals, Initializes the Flash interface and the Systick. */
  HAL_Init();

  /* Configure the system clock */
  SystemClock_Config();

  /* Initialize all configured peripherals */
  MX_GPIO_Init();
  MX_DMA_Init();
  MX_TIM3_Init();
  MX_ADC1_Init();
  MX_TIM2_Init();
  MX_TIM1_Init();
  MX_SPI2_Init();
  MX_TIM4_Init();
  MX_TIM5_Init();
  MX_SPI1_Init();
  MX_CAN1_Init();
  MX_ADC2_Init();
  MX_I2C1_Init();
  MX_SPI3_Init();
  MX_USART1_UART_Init();
  MX_TIM9_Init();
  MX_IWDG_Init();
  MX_USART3_UART_Init();
  MX_TIM13_Init();
  MX_TIM6_Init();
  MX_TIM8_Init();

  /* Initialize interrupts */
  MX_NVIC_Init();
  /* USER CODE BEGIN 2 */
  MX_USB_OTG_FS_PCD_Init();
  HAL_GPIO_WritePin(LED_SYS_GPIO_Port, LED_SYS_Pin, GPIO_PIN_SET);
  HAL_GPIO_WritePin(LED_CLIP_GPIO_Port, LED_CLIP_Pin, GPIO_PIN_SET);
  HAL_GPIO_WritePin(LED_ERR_GPIO_Port, LED_ERR_Pin, GPIO_PIN_SET);
  HAL_Delay(100);

  // Backup domain enable
//  HAL_PWR_EnableBkUpAccess();
//  HAL_PWR_EnableBkUpReg();
//  __HAL_RCC_BKPSRAM_CLK_ENABLE();
  //BKPSRAM_BASE
  // Backup sram enabled by boot assembly

  /* USER CODE END 2 */

  /* Init scheduler */
  osKernelInitialize();

  /* Create the thread(s) */
  /* creation of defaultTask */
  defaultTaskHandle = osThreadNew(StartDefaultTask, NULL, &defaultTask_attributes);

  /* Start scheduler */
  osKernelStart();

  /* We should never get here as control is now taken by the scheduler */
  /* Infinite loop */
  while (1)
  {

  }
}

void SystemClock_Config(void)
{
  RCC_OscInitTypeDef RCC_OscInitStruct = {0};
  RCC_ClkInitTypeDef RCC_ClkInitStruct = {0};

  /** Configure the main internal regulator output voltage
  */
  __HAL_RCC_PWR_CLK_ENABLE();
  __HAL_PWR_VOLTAGESCALING_CONFIG(PWR_REGULATOR_VOLTAGE_SCALE1);

  /** Initializes the RCC Oscillators according to the specified parameters
  * in the RCC_OscInitTypeDef structure.
  */
  RCC_OscInitStruct.OscillatorType = RCC_OSCILLATORTYPE_LSI|RCC_OSCILLATORTYPE_HSE;
  RCC_OscInitStruct.HSEState = RCC_HSE_ON;
  RCC_OscInitStruct.LSIState = RCC_LSI_ON;
  RCC_OscInitStruct.PLL.PLLState = RCC_PLL_ON;
  RCC_OscInitStruct.PLL.PLLSource = RCC_PLLSOURCE_HSE;
  RCC_OscInitStruct.PLL.PLLM = 4;
  RCC_OscInitStruct.PLL.PLLN = 168;
  RCC_OscInitStruct.PLL.PLLP = RCC_PLLP_DIV2;
  RCC_OscInitStruct.PLL.PLLQ = 7;
  if (HAL_RCC_OscConfig(&RCC_OscInitStruct) != HAL_OK)
  {
    Error_Handler();
  }

  /** Initializes the CPU, AHB and APB buses clocks
  */
  RCC_ClkInitStruct.ClockType = RCC_CLOCKTYPE_HCLK|RCC_CLOCKTYPE_SYSCLK
                              |RCC_CLOCKTYPE_PCLK1|RCC_CLOCKTYPE_PCLK2;
  RCC_ClkInitStruct.SYSCLKSource = RCC_SYSCLKSOURCE_PLLCLK;
  RCC_ClkInitStruct.AHBCLKDivider = RCC_SYSCLK_DIV1;
  RCC_ClkInitStruct.APB1CLKDivider = RCC_HCLK_DIV4;
  RCC_ClkInitStruct.APB2CLKDivider = RCC_HCLK_DIV2;

  if (HAL_RCC_ClockConfig(&RCC_ClkInitStruct, FLASH_LATENCY_5) != HAL_OK)
  {
    Error_Handler();
  }
}

/**
  * @brief NVIC Configuration.
  * @retval None
  */
static void MX_NVIC_Init(void)
{
  /* DMA2_Stream0_IRQn interrupt configuration */
  HAL_NVIC_SetPriority(DMA2_Stream0_IRQn, 6, 0);
  HAL_NVIC_EnableIRQ(DMA2_Stream0_IRQn);
  /* TIM3_IRQn interrupt configuration */
  HAL_NVIC_SetPriority(TIM3_IRQn, 6, 0);
  HAL_NVIC_EnableIRQ(TIM3_IRQn);
}

static void MX_ADC1_Init(void)
{

  ADC_ChannelConfTypeDef sConfig = {0};

  /** Configure the global features of the ADC (Clock, Resolution, Data Alignment and number of conversion)
  */
  hadc1.Instance = ADC1;
  hadc1.Init.ClockPrescaler = ADC_CLOCK_SYNC_PCLK_DIV4;
  hadc1.Init.Resolution = ADC_RESOLUTION_12B;
  hadc1.Init.ScanConvMode = ENABLE;
  hadc1.Init.ContinuousConvMode = DISABLE;
  hadc1.Init.DiscontinuousConvMode = DISABLE;
  hadc1.Init.ExternalTrigConvEdge = ADC_EXTERNALTRIGCONVEDGE_RISING;
  hadc1.Init.ExternalTrigConv = ADC_EXTERNALTRIGCONV_T4_CC4;
  hadc1.Init.DataAlign = ADC_DATAALIGN_RIGHT;
  hadc1.Init.NbrOfConversion = 8;
  hadc1.Init.DMAContinuousRequests = ENABLE;
  hadc1.Init.EOCSelection = ADC_EOC_SINGLE_CONV;
  if (HAL_ADC_Init(&hadc1) != HAL_OK)
  {
    Error_Handler();
  }

  /** Configure for the selected ADC regular channel its corresponding rank in the sequencer and its sample time.
  */
  sConfig.Channel = ADC_CHANNEL_3;
  sConfig.Rank = 1;
  sConfig.SamplingTime = ADC_SAMPLETIME_84CYCLES;
  if (HAL_ADC_ConfigChannel(&hadc1, &sConfig) != HAL_OK)
  {
    Error_Handler();
  }

  /** Configure for the selected ADC regular channel its corresponding rank in the sequencer and its sample time.
  */
  sConfig.Channel = ADC_CHANNEL_2;
  sConfig.Rank = 2;
  if (HAL_ADC_ConfigChannel(&hadc1, &sConfig) != HAL_OK)
  {
    Error_Handler();
  }

  /** Configure for the selected ADC regular channel its corresponding rank in the sequencer and its sample time.
  */
  sConfig.Channel = ADC_CHANNEL_13;
  sConfig.Rank = 3;
  if (HAL_ADC_ConfigChannel(&hadc1, &sConfig) != HAL_OK)
  {
    Error_Handler();
  }

  /** Configure for the selected ADC regular channel its corresponding rank in the sequencer and its sample time.
  */
  sConfig.Channel = ADC_CHANNEL_12;
  sConfig.Rank = 4;
  if (HAL_ADC_ConfigChannel(&hadc1, &sConfig) != HAL_OK)
  {
    Error_Handler();
  }

  /** Configure for the selected ADC regular channel its corresponding rank in the sequencer and its sample time.
  */
  sConfig.Channel = ADC_CHANNEL_11;
  sConfig.Rank = 5;
  if (HAL_ADC_ConfigChannel(&hadc1, &sConfig) != HAL_OK)
  {
    Error_Handler();
  }

  /** Configure for the selected ADC regular channel its corresponding rank in the sequencer and its sample time.
  */
  sConfig.Channel = ADC_CHANNEL_10;
  sConfig.Rank = 6;
  if (HAL_ADC_ConfigChannel(&hadc1, &sConfig) != HAL_OK)
  {
    Error_Handler();
  }

  /** Configure for the selected ADC regular channel its corresponding rank in the sequencer and its sample time.
  */
  sConfig.Channel = ADC_CHANNEL_TEMPSENSOR;
  sConfig.Rank = 7;
  sConfig.SamplingTime = ADC_SAMPLETIME_56CYCLES;
  if (HAL_ADC_ConfigChannel(&hadc1, &sConfig) != HAL_OK)
  {
    Error_Handler();
  }

  /** Configure for the selected ADC regular channel its corresponding rank in the sequencer and its sample time.
  */
  sConfig.Channel = ADC_CHANNEL_VREFINT;
  sConfig.Rank = 8;
  if (HAL_ADC_ConfigChannel(&hadc1, &sConfig) != HAL_OK)
  {
    Error_Handler();
  }

}

static void MX_ADC2_Init(void)
{

  ADC_ChannelConfTypeDef sConfig = {0};

  /** Configure the global features of the ADC (Clock, Resolution, Data Alignment and number of conversion)
  */
  hadc2.Instance = ADC2;
  hadc2.Init.ClockPrescaler = ADC_CLOCK_SYNC_PCLK_DIV4;
  hadc2.Init.Resolution = ADC_RESOLUTION_12B;
  hadc2.Init.ScanConvMode = ENABLE;
  hadc2.Init.ContinuousConvMode = DISABLE;
  hadc2.Init.DiscontinuousConvMode = DISABLE;
  hadc2.Init.ExternalTrigConvEdge = ADC_EXTERNALTRIGCONVEDGE_RISINGFALLING;
  hadc2.Init.ExternalTrigConv = ADC_EXTERNALTRIGCONV_T4_CC4;
  hadc2.Init.DataAlign = ADC_DATAALIGN_RIGHT;
  hadc2.Init.NbrOfConversion = 2;
  hadc2.Init.DMAContinuousRequests = ENABLE;
  hadc2.Init.EOCSelection = ADC_EOC_SINGLE_CONV;
  if (HAL_ADC_Init(&hadc2) != HAL_OK)
  {
    Error_Handler();
  }

  /** Configure for the selected ADC regular channel its corresponding rank in the sequencer and its sample time.
  */
  sConfig.Channel = ADC_CHANNEL_14;
  sConfig.Rank = 1;
  sConfig.SamplingTime = ADC_SAMPLETIME_84CYCLES;
  if (HAL_ADC_ConfigChannel(&hadc2, &sConfig) != HAL_OK)
  {
    Error_Handler();
  }

  /** Configure for the selected ADC regular channel its corresponding rank in the sequencer and its sample time.
  */
  sConfig.Channel = ADC_CHANNEL_15;
  sConfig.Rank = 2;
  if (HAL_ADC_ConfigChannel(&hadc2, &sConfig) != HAL_OK)
  {
    Error_Handler();
  }

}

static void MX_CAN1_Init(void)
{

  hcan1.Instance = CAN1;
  hcan1.Init.Prescaler = 6;
  hcan1.Init.Mode = CAN_MODE_NORMAL;
  hcan1.Init.SyncJumpWidth = CAN_SJW_1TQ;
  hcan1.Init.TimeSeg1 = CAN_BS1_11TQ;
  hcan1.Init.TimeSeg2 = CAN_BS2_2TQ;
  hcan1.Init.TimeTriggeredMode = DISABLE;
  hcan1.Init.AutoBusOff = DISABLE;
  hcan1.Init.AutoWakeUp = DISABLE;
  hcan1.Init.AutoRetransmission = ENABLE;
  hcan1.Init.ReceiveFifoLocked = DISABLE;
  hcan1.Init.TransmitFifoPriority = DISABLE;
  if (HAL_CAN_Init(&hcan1) != HAL_OK)
  {
    Error_Handler();
  }

}

static void MX_I2C1_Init(void)
{

  hi2c1.Instance = I2C1;
  hi2c1.Init.ClockSpeed = 100000;
  hi2c1.Init.DutyCycle = I2C_DUTYCYCLE_2;
  hi2c1.Init.OwnAddress1 = 0;
  hi2c1.Init.AddressingMode = I2C_ADDRESSINGMODE_7BIT;
  hi2c1.Init.DualAddressMode = I2C_DUALADDRESS_DISABLE;
  hi2c1.Init.OwnAddress2 = 0;
  hi2c1.Init.GeneralCallMode = I2C_GENERALCALL_DISABLE;
  hi2c1.Init.NoStretchMode = I2C_NOSTRETCH_DISABLE;
  if (HAL_I2C_Init(&hi2c1) != HAL_OK)
  {
    Error_Handler();
  }

}

static void MX_IWDG_Init(void)
{

  hiwdg.Instance = IWDG;
  hiwdg.Init.Prescaler = IWDG_PRESCALER_16;
  hiwdg.Init.Reload = 4095;
  if (HAL_IWDG_Init(&hiwdg) != HAL_OK)
  {
    Error_Handler();
  }

}

static void MX_SPI1_Init(void)
{

  /* SPI1 parameter configuration*/
  hspi1.Instance = SPI1;
  hspi1.Init.Mode = SPI_MODE_MASTER;
  hspi1.Init.Direction = SPI_DIRECTION_2LINES;
  hspi1.Init.DataSize = SPI_DATASIZE_8BIT;
  hspi1.Init.CLKPolarity = SPI_POLARITY_HIGH;
  hspi1.Init.CLKPhase = SPI_PHASE_2EDGE;
  hspi1.Init.NSS = SPI_NSS_SOFT;
  hspi1.Init.BaudRatePrescaler = SPI_BAUDRATEPRESCALER_8;
  hspi1.Init.FirstBit = SPI_FIRSTBIT_MSB;
  hspi1.Init.TIMode = SPI_TIMODE_DISABLE;
  hspi1.Init.CRCCalculation = SPI_CRCCALCULATION_DISABLE;
  hspi1.Init.CRCPolynomial = 10;
  if (HAL_SPI_Init(&hspi1) != HAL_OK)
  {
    Error_Handler();
  }

}

static void MX_SPI2_Init(void)
{

  /* SPI2 parameter configuration*/
  hspi2.Instance = SPI2;
  hspi2.Init.Mode = SPI_MODE_MASTER;
  hspi2.Init.Direction = SPI_DIRECTION_2LINES;
  hspi2.Init.DataSize = SPI_DATASIZE_8BIT;
  hspi2.Init.CLKPolarity = SPI_POLARITY_LOW;
  hspi2.Init.CLKPhase = SPI_PHASE_1EDGE;
  hspi2.Init.NSS = SPI_NSS_SOFT;
  hspi2.Init.BaudRatePrescaler = SPI_BAUDRATEPRESCALER_32;
  hspi2.Init.FirstBit = SPI_FIRSTBIT_MSB;
  hspi2.Init.TIMode = SPI_TIMODE_DISABLE;
  hspi2.Init.CRCCalculation = SPI_CRCCALCULATION_DISABLE;
  hspi2.Init.CRCPolynomial = 10;
  if (HAL_SPI_Init(&hspi2) != HAL_OK)
  {
    Error_Handler();
  }

}

static void MX_SPI3_Init(void)
{

  /* SPI3 parameter configuration*/
  hspi3.Instance = SPI3;
  hspi3.Init.Mode = SPI_MODE_MASTER;
  hspi3.Init.Direction = SPI_DIRECTION_2LINES;
  hspi3.Init.DataSize = SPI_DATASIZE_8BIT;
  hspi3.Init.CLKPolarity = SPI_POLARITY_LOW;
  hspi3.Init.CLKPhase = SPI_PHASE_1EDGE;
  hspi3.Init.NSS = SPI_NSS_SOFT;
  hspi3.Init.BaudRatePrescaler = SPI_BAUDRATEPRESCALER_32;
  hspi3.Init.FirstBit = SPI_FIRSTBIT_MSB;
  hspi3.Init.TIMode = SPI_TIMODE_DISABLE;
  hspi3.Init.CRCCalculation = SPI_CRCCALCULATION_DISABLE;
  hspi3.Init.CRCPolynomial = 10;
  if (HAL_SPI_Init(&hspi3) != HAL_OK)
  {
    Error_Handler();
  }

}

static void MX_TIM1_Init(void)
{

  TIM_ClockConfigTypeDef sClockSourceConfig = {0};
  TIM_MasterConfigTypeDef sMasterConfig = {0};
  TIM_OC_InitTypeDef sConfigOC = {0};
  TIM_BreakDeadTimeConfigTypeDef sBreakDeadTimeConfig = {0};

  htim1.Instance = TIM1;
  htim1.Init.Prescaler = 0;
  htim1.Init.CounterMode = TIM_COUNTERMODE_UP;
  htim1.Init.Period = 0xffff;
  htim1.Init.ClockDivision = TIM_CLOCKDIVISION_DIV1;
  htim1.Init.RepetitionCounter = 0;
  htim1.Init.AutoReloadPreload = TIM_AUTORELOAD_PRELOAD_ENABLE;
  if (HAL_TIM_Base_Init(&htim1) != HAL_OK)
  {
    Error_Handler();
  }
  sClockSourceConfig.ClockSource = TIM_CLOCKSOURCE_INTERNAL;
  if (HAL_TIM_ConfigClockSource(&htim1, &sClockSourceConfig) != HAL_OK)
  {
    Error_Handler();
  }
  if (HAL_TIM_PWM_Init(&htim1) != HAL_OK)
  {
    Error_Handler();
  }
  sMasterConfig.MasterOutputTrigger = TIM_TRGO_RESET;
  sMasterConfig.MasterSlaveMode = TIM_MASTERSLAVEMODE_DISABLE;
  if (HAL_TIMEx_MasterConfigSynchronization(&htim1, &sMasterConfig) != HAL_OK)
  {
    Error_Handler();
  }
  sConfigOC.OCMode = TIM_OCMODE_PWM1;
  sConfigOC.Pulse = 0;
  sConfigOC.OCPolarity = TIM_OCPOLARITY_HIGH;
  sConfigOC.OCNPolarity = TIM_OCNPOLARITY_HIGH;
  sConfigOC.OCFastMode = TIM_OCFAST_DISABLE;
  sConfigOC.OCIdleState = TIM_OCIDLESTATE_RESET;
  sConfigOC.OCNIdleState = TIM_OCNIDLESTATE_RESET;
  if (HAL_TIM_PWM_ConfigChannel(&htim1, &sConfigOC, TIM_CHANNEL_1) != HAL_OK)
  {
    Error_Handler();
  }
  if (HAL_TIM_PWM_ConfigChannel(&htim1, &sConfigOC, TIM_CHANNEL_2) != HAL_OK)
  {
    Error_Handler();
  }
  if (HAL_TIM_PWM_ConfigChannel(&htim1, &sConfigOC, TIM_CHANNEL_3) != HAL_OK)
  {
    Error_Handler();
  }
  if (HAL_TIM_PWM_ConfigChannel(&htim1, &sConfigOC, TIM_CHANNEL_4) != HAL_OK)
  {
    Error_Handler();
  }
  sBreakDeadTimeConfig.OffStateRunMode = TIM_OSSR_DISABLE;
  sBreakDeadTimeConfig.OffStateIDLEMode = TIM_OSSI_DISABLE;
  sBreakDeadTimeConfig.LockLevel = TIM_LOCKLEVEL_OFF;
  sBreakDeadTimeConfig.DeadTime = 0;
  sBreakDeadTimeConfig.BreakState = TIM_BREAK_DISABLE;
  sBreakDeadTimeConfig.BreakPolarity = TIM_BREAKPOLARITY_HIGH;
  sBreakDeadTimeConfig.AutomaticOutput = TIM_AUTOMATICOUTPUT_DISABLE;
  if (HAL_TIMEx_ConfigBreakDeadTime(&htim1, &sBreakDeadTimeConfig) != HAL_OK)
  {
    Error_Handler();
  }
  HAL_TIM_MspPostInit(&htim1);

}

static void MX_TIM2_Init(void)
{

  TIM_ClockConfigTypeDef sClockSourceConfig = {0};
  TIM_SlaveConfigTypeDef sSlaveConfig = {0};
  TIM_IC_InitTypeDef sConfigIC = {0};
  TIM_MasterConfigTypeDef sMasterConfig = {0};

  htim2.Instance = TIM2;
  htim2.Init.Prescaler = 0;
  htim2.Init.CounterMode = TIM_COUNTERMODE_UP;
  htim2.Init.Period = 0xffffffff;
  htim2.Init.ClockDivision = TIM_CLOCKDIVISION_DIV1;
  htim2.Init.AutoReloadPreload = TIM_AUTORELOAD_PRELOAD_DISABLE;
  if (HAL_TIM_Base_Init(&htim2) != HAL_OK)
  {
    Error_Handler();
  }
  sClockSourceConfig.ClockSource = TIM_CLOCKSOURCE_INTERNAL;
  if (HAL_TIM_ConfigClockSource(&htim2, &sClockSourceConfig) != HAL_OK)
  {
    Error_Handler();
  }
  if (HAL_TIM_IC_Init(&htim2) != HAL_OK)
  {
    Error_Handler();
  }
  sSlaveConfig.SlaveMode = TIM_SLAVEMODE_RESET;
  sSlaveConfig.InputTrigger = TIM_TS_TI2FP2;
  sSlaveConfig.TriggerPolarity = TIM_INPUTCHANNELPOLARITY_FALLING;
  sSlaveConfig.TriggerPrescaler = TIM_ICPSC_DIV1;
  sSlaveConfig.TriggerFilter = 0;
  if (HAL_TIM_SlaveConfigSynchro(&htim2, &sSlaveConfig) != HAL_OK)
  {
    Error_Handler();
  }
  sConfigIC.ICPolarity = TIM_INPUTCHANNELPOLARITY_RISING;
  sConfigIC.ICSelection = TIM_ICSELECTION_INDIRECTTI;
  sConfigIC.ICPrescaler = TIM_ICPSC_DIV1;
  sConfigIC.ICFilter = 0;
  if (HAL_TIM_IC_ConfigChannel(&htim2, &sConfigIC, TIM_CHANNEL_1) != HAL_OK)
  {
    Error_Handler();
  }
  sConfigIC.ICPolarity = TIM_INPUTCHANNELPOLARITY_FALLING;
  sConfigIC.ICSelection = TIM_ICSELECTION_DIRECTTI;
  if (HAL_TIM_IC_ConfigChannel(&htim2, &sConfigIC, TIM_CHANNEL_2) != HAL_OK)
  {
    Error_Handler();
  }
  sMasterConfig.MasterOutputTrigger = TIM_TRGO_RESET;
  sMasterConfig.MasterSlaveMode = TIM_MASTERSLAVEMODE_DISABLE;
  if (HAL_TIMEx_MasterConfigSynchronization(&htim2, &sMasterConfig) != HAL_OK)
  {
    Error_Handler();
  }

}

static void MX_TIM3_Init(void)
{

  TIM_Encoder_InitTypeDef sConfig = {0};
  TIM_MasterConfigTypeDef sMasterConfig = {0};

  htim3.Instance = TIM3;
  htim3.Init.Prescaler = 0;
  htim3.Init.CounterMode = TIM_COUNTERMODE_CENTERALIGNED1;
  htim3.Init.Period = 0xffff;
  htim3.Init.ClockDivision = TIM_CLOCKDIVISION_DIV1;
  htim3.Init.AutoReloadPreload = TIM_AUTORELOAD_PRELOAD_DISABLE;
  sConfig.EncoderMode = TIM_ENCODERMODE_TI12;
  sConfig.IC1Polarity = TIM_ICPOLARITY_FALLING;
  sConfig.IC1Selection = TIM_ICSELECTION_DIRECTTI;
  sConfig.IC1Prescaler = TIM_ICPSC_DIV1;
  sConfig.IC1Filter = 0;
  sConfig.IC2Polarity = TIM_ICPOLARITY_FALLING;
  sConfig.IC2Selection = TIM_ICSELECTION_DIRECTTI;
  sConfig.IC2Prescaler = TIM_ICPSC_DIV1;
  sConfig.IC2Filter = 0;
  if (HAL_TIM_Encoder_Init(&htim3, &sConfig) != HAL_OK)
  {
    Error_Handler();
  }
  sMasterConfig.MasterOutputTrigger = TIM_TRGO_RESET;
  sMasterConfig.MasterSlaveMode = TIM_MASTERSLAVEMODE_DISABLE;
  if (HAL_TIMEx_MasterConfigSynchronization(&htim3, &sMasterConfig) != HAL_OK)
  {
    Error_Handler();
  }

}

static void MX_TIM4_Init(void)
{

  TIM_ClockConfigTypeDef sClockSourceConfig = {0};
  TIM_MasterConfigTypeDef sMasterConfig = {0};
  TIM_OC_InitTypeDef sConfigOC = {0};

  htim4.Instance = TIM4;
  htim4.Init.Prescaler = 84-1;
  htim4.Init.CounterMode = TIM_COUNTERMODE_UP;
  htim4.Init.Period = 100;
  htim4.Init.ClockDivision = TIM_CLOCKDIVISION_DIV1;
  htim4.Init.AutoReloadPreload = TIM_AUTORELOAD_PRELOAD_DISABLE;
  if (HAL_TIM_Base_Init(&htim4) != HAL_OK)
  {
    Error_Handler();
  }
  sClockSourceConfig.ClockSource = TIM_CLOCKSOURCE_INTERNAL;
  if (HAL_TIM_ConfigClockSource(&htim4, &sClockSourceConfig) != HAL_OK)
  {
    Error_Handler();
  }
  if (HAL_TIM_PWM_Init(&htim4) != HAL_OK)
  {
    Error_Handler();
  }
  sMasterConfig.MasterOutputTrigger = TIM_TRGO_RESET;
  sMasterConfig.MasterSlaveMode = TIM_MASTERSLAVEMODE_DISABLE;
  if (HAL_TIMEx_MasterConfigSynchronization(&htim4, &sMasterConfig) != HAL_OK)
  {
    Error_Handler();
  }
  sConfigOC.OCMode = TIM_OCMODE_PWM1;
  sConfigOC.Pulse = 50;
  sConfigOC.OCPolarity = TIM_OCPOLARITY_HIGH;
  sConfigOC.OCFastMode = TIM_OCFAST_DISABLE;
  if (HAL_TIM_PWM_ConfigChannel(&htim4, &sConfigOC, TIM_CHANNEL_4) != HAL_OK)
  {
    Error_Handler();
  }
  /* USER CODE BEGIN TIM4_Init 2 */
  HAL_TIM_PWM_Start(&htim4, TIM_CHANNEL_4);
  /* USER CODE END TIM4_Init 2 */

}

static void MX_TIM5_Init(void)
{

  TIM_ClockConfigTypeDef sClockSourceConfig = {0};
  TIM_SlaveConfigTypeDef sSlaveConfig = {0};
  TIM_IC_InitTypeDef sConfigIC = {0};
  TIM_MasterConfigTypeDef sMasterConfig = {0};

  htim5.Instance = TIM5;
  htim5.Init.Prescaler = 0;
  htim5.Init.CounterMode = TIM_COUNTERMODE_UP;
  htim5.Init.Period = 0xffffffff;
  htim5.Init.ClockDivision = TIM_CLOCKDIVISION_DIV1;
  htim5.Init.AutoReloadPreload = TIM_AUTORELOAD_PRELOAD_DISABLE;
  if (HAL_TIM_Base_Init(&htim5) != HAL_OK)
  {
    Error_Handler();
  }
  sClockSourceConfig.ClockSource = TIM_CLOCKSOURCE_INTERNAL;
  if (HAL_TIM_ConfigClockSource(&htim5, &sClockSourceConfig) != HAL_OK)
  {
    Error_Handler();
  }
  if (HAL_TIM_IC_Init(&htim5) != HAL_OK)
  {
    Error_Handler();
  }
  sSlaveConfig.SlaveMode = TIM_SLAVEMODE_RESET;
  sSlaveConfig.InputTrigger = TIM_TS_TI1FP1;
  sSlaveConfig.TriggerPolarity = TIM_INPUTCHANNELPOLARITY_RISING;
  sSlaveConfig.TriggerPrescaler = TIM_ICPSC_DIV1;
  sSlaveConfig.TriggerFilter = 0;
  if (HAL_TIM_SlaveConfigSynchro(&htim5, &sSlaveConfig) != HAL_OK)
  {
    Error_Handler();
  }
  sConfigIC.ICPolarity = TIM_INPUTCHANNELPOLARITY_RISING;
  sConfigIC.ICSelection = TIM_ICSELECTION_DIRECTTI;
  sConfigIC.ICPrescaler = TIM_ICPSC_DIV1;
  sConfigIC.ICFilter = 0;
  if (HAL_TIM_IC_ConfigChannel(&htim5, &sConfigIC, TIM_CHANNEL_1) != HAL_OK)
  {
    Error_Handler();
  }
  sConfigIC.ICPolarity = TIM_INPUTCHANNELPOLARITY_FALLING;
  sConfigIC.ICSelection = TIM_ICSELECTION_INDIRECTTI;
  if (HAL_TIM_IC_ConfigChannel(&htim5, &sConfigIC, TIM_CHANNEL_2) != HAL_OK)
  {
    Error_Handler();
  }
  sMasterConfig.MasterOutputTrigger = TIM_TRGO_RESET;
  sMasterConfig.MasterSlaveMode = TIM_MASTERSLAVEMODE_DISABLE;
  if (HAL_TIMEx_MasterConfigSynchronization(&htim5, &sMasterConfig) != HAL_OK)
  {
    Error_Handler();
  }

}

static void MX_TIM6_Init(void)
{

  TIM_MasterConfigTypeDef sMasterConfig = {0};

  htim6.Instance = TIM6;
  htim6.Init.Prescaler = 167;
  htim6.Init.CounterMode = TIM_COUNTERMODE_UP;
  htim6.Init.Period = 65535;
  htim6.Init.AutoReloadPreload = TIM_AUTORELOAD_PRELOAD_DISABLE;
  if (HAL_TIM_Base_Init(&htim6) != HAL_OK)
  {
    Error_Handler();
  }
  sMasterConfig.MasterOutputTrigger = TIM_TRGO_RESET;
  sMasterConfig.MasterSlaveMode = TIM_MASTERSLAVEMODE_DISABLE;
  if (HAL_TIMEx_MasterConfigSynchronization(&htim6, &sMasterConfig) != HAL_OK)
  {
    Error_Handler();
  }

}

static void MX_TIM8_Init(void)
{

  TIM_ClockConfigTypeDef sClockSourceConfig = {0};
  TIM_MasterConfigTypeDef sMasterConfig = {0};
  TIM_OC_InitTypeDef sConfigOC = {0};
  TIM_BreakDeadTimeConfigTypeDef sBreakDeadTimeConfig = {0};

  htim8.Instance = TIM8;
  htim8.Init.Prescaler = 0;
  htim8.Init.CounterMode = TIM_COUNTERMODE_UP;
  htim8.Init.Period = 65535;
  htim8.Init.ClockDivision = TIM_CLOCKDIVISION_DIV1;
  htim8.Init.RepetitionCounter = 0;
  htim8.Init.AutoReloadPreload = TIM_AUTORELOAD_PRELOAD_DISABLE;
  if (HAL_TIM_Base_Init(&htim8) != HAL_OK)
  {
    Error_Handler();
  }
  sClockSourceConfig.ClockSource = TIM_CLOCKSOURCE_INTERNAL;
  if (HAL_TIM_ConfigClockSource(&htim8, &sClockSourceConfig) != HAL_OK)
  {
    Error_Handler();
  }
  if (HAL_TIM_OC_Init(&htim8) != HAL_OK)
  {
    Error_Handler();
  }
  sMasterConfig.MasterOutputTrigger = TIM_TRGO_OC1REF;
  sMasterConfig.MasterSlaveMode = TIM_MASTERSLAVEMODE_DISABLE;
  if (HAL_TIMEx_MasterConfigSynchronization(&htim8, &sMasterConfig) != HAL_OK)
  {
    Error_Handler();
  }
  sConfigOC.OCMode = TIM_OCMODE_TIMING;
  sConfigOC.Pulse = 0;
  sConfigOC.OCPolarity = TIM_OCPOLARITY_HIGH;
  sConfigOC.OCNPolarity = TIM_OCNPOLARITY_HIGH;
  sConfigOC.OCFastMode = TIM_OCFAST_DISABLE;
  sConfigOC.OCIdleState = TIM_OCIDLESTATE_RESET;
  sConfigOC.OCNIdleState = TIM_OCNIDLESTATE_RESET;
  if (HAL_TIM_OC_ConfigChannel(&htim8, &sConfigOC, TIM_CHANNEL_1) != HAL_OK)
  {
    Error_Handler();
  }
  sBreakDeadTimeConfig.OffStateRunMode = TIM_OSSR_DISABLE;
  sBreakDeadTimeConfig.OffStateIDLEMode = TIM_OSSI_DISABLE;
  sBreakDeadTimeConfig.LockLevel = TIM_LOCKLEVEL_OFF;
  sBreakDeadTimeConfig.DeadTime = 0;
  sBreakDeadTimeConfig.BreakState = TIM_BREAK_DISABLE;
  sBreakDeadTimeConfig.BreakPolarity = TIM_BREAKPOLARITY_HIGH;
  sBreakDeadTimeConfig.AutomaticOutput = TIM_AUTOMATICOUTPUT_DISABLE;
  if (HAL_TIMEx_ConfigBreakDeadTime(&htim8, &sBreakDeadTimeConfig) != HAL_OK)
  {
    Error_Handler();
  }

}

static void MX_TIM9_Init(void)
{

  TIM_ClockConfigTypeDef sClockSourceConfig = {0};

  htim9.Instance = TIM9;
  htim9.Init.Prescaler = 0;
  htim9.Init.CounterMode = TIM_COUNTERMODE_UP;
  htim9.Init.Period = 65535;
  htim9.Init.ClockDivision = TIM_CLOCKDIVISION_DIV1;
  htim9.Init.AutoReloadPreload = TIM_AUTORELOAD_PRELOAD_DISABLE;
  if (HAL_TIM_Base_Init(&htim9) != HAL_OK)
  {
    Error_Handler();
  }
  sClockSourceConfig.ClockSource = TIM_CLOCKSOURCE_INTERNAL;
  if (HAL_TIM_ConfigClockSource(&htim9, &sClockSourceConfig) != HAL_OK)
  {
    Error_Handler();
  }

}

static void MX_TIM13_Init(void)
{

  htim13.Instance = TIM13;
  htim13.Init.Prescaler = 167;
  htim13.Init.CounterMode = TIM_COUNTERMODE_UP;
  htim13.Init.Period = 100;
  htim13.Init.ClockDivision = TIM_CLOCKDIVISION_DIV1;
  htim13.Init.AutoReloadPreload = TIM_AUTORELOAD_PRELOAD_DISABLE;
  if (HAL_TIM_Base_Init(&htim13) != HAL_OK)
  {
    Error_Handler();
  }

}

static void MX_USART1_UART_Init(void)
{

  huart1.Instance = USART1;
  huart1.Init.BaudRate = 115200;
  huart1.Init.WordLength = UART_WORDLENGTH_8B;
  huart1.Init.StopBits = UART_STOPBITS_1;
  huart1.Init.Parity = UART_PARITY_NONE;
  huart1.Init.Mode = UART_MODE_TX_RX;
  huart1.Init.HwFlowCtl = UART_HWCONTROL_NONE;
  huart1.Init.OverSampling = UART_OVERSAMPLING_16;
  if (HAL_UART_Init(&huart1) != HAL_OK)
  {
    Error_Handler();
  }

}

static void MX_USART3_UART_Init(void)
{

  huart3.Instance = USART3;
  huart3.Init.BaudRate = 460800;
  huart3.Init.WordLength = UART_WORDLENGTH_8B;
  huart3.Init.StopBits = UART_STOPBITS_1;
  huart3.Init.Parity = UART_PARITY_NONE;
  huart3.Init.Mode = UART_MODE_TX_RX;
  huart3.Init.HwFlowCtl = UART_HWCONTROL_NONE;
  huart3.Init.OverSampling = UART_OVERSAMPLING_16;
  if (HAL_UART_Init(&huart3) != HAL_OK)
  {
    Error_Handler();
  }

}

void MX_USB_OTG_FS_PCD_Init(void)
{

  hpcd_USB_OTG_FS.Instance = USB_OTG_FS;
  hpcd_USB_OTG_FS.Init.dev_endpoints = 4;
  hpcd_USB_OTG_FS.Init.speed = PCD_SPEED_FULL;
  hpcd_USB_OTG_FS.Init.dma_enable = DISABLE;
  hpcd_USB_OTG_FS.Init.phy_itface = PCD_PHY_EMBEDDED;
  hpcd_USB_OTG_FS.Init.Sof_enable = DISABLE;
  hpcd_USB_OTG_FS.Init.low_power_enable = DISABLE;
  hpcd_USB_OTG_FS.Init.lpm_enable = DISABLE;
  hpcd_USB_OTG_FS.Init.vbus_sensing_enable = ENABLE;
  hpcd_USB_OTG_FS.Init.use_dedicated_ep1 = DISABLE;
  if (HAL_PCD_Init(&hpcd_USB_OTG_FS) != HAL_OK)
  {
    Error_Handler();
  }

}

static void MX_DMA_Init(void)
{

  /* DMA controller clock enable */
  __HAL_RCC_DMA2_CLK_ENABLE();
  __HAL_RCC_DMA1_CLK_ENABLE();

  /* DMA interrupt init */
  /* DMA1_Stream2_IRQn interrupt configuration */
  HAL_NVIC_SetPriority(DMA1_Stream2_IRQn, 5, 0);
  HAL_NVIC_EnableIRQ(DMA1_Stream2_IRQn);
  /* DMA1_Stream3_IRQn interrupt configuration */
  HAL_NVIC_SetPriority(DMA1_Stream3_IRQn, 9, 0);
  HAL_NVIC_EnableIRQ(DMA1_Stream3_IRQn);
  /* DMA1_Stream4_IRQn interrupt configuration */
  HAL_NVIC_SetPriority(DMA1_Stream4_IRQn, 9, 0);
  HAL_NVIC_EnableIRQ(DMA1_Stream4_IRQn);
  /* DMA1_Stream5_IRQn interrupt configuration */
  HAL_NVIC_SetPriority(DMA1_Stream5_IRQn, 5, 0);
  HAL_NVIC_EnableIRQ(DMA1_Stream5_IRQn);
  /* DMA2_Stream2_IRQn interrupt configuration */
  HAL_NVIC_SetPriority(DMA2_Stream2_IRQn, 10, 0);
  HAL_NVIC_EnableIRQ(DMA2_Stream2_IRQn);
  /* DMA2_Stream3_IRQn interrupt configuration */
  HAL_NVIC_SetPriority(DMA2_Stream3_IRQn, 6, 0);
  HAL_NVIC_EnableIRQ(DMA2_Stream3_IRQn);
  /* DMA2_Stream4_IRQn interrupt configuration */
  HAL_NVIC_SetPriority(DMA2_Stream4_IRQn, 10, 0);
  HAL_NVIC_EnableIRQ(DMA2_Stream4_IRQn);

}

static void MX_GPIO_Init(void)
{
  GPIO_InitTypeDef GPIO_InitStruct = {0};

  /* GPIO Ports Clock Enable */
  __HAL_RCC_GPIOE_CLK_ENABLE();
  __HAL_RCC_GPIOC_CLK_ENABLE();
  __HAL_RCC_GPIOH_CLK_ENABLE();
  __HAL_RCC_GPIOA_CLK_ENABLE();
  __HAL_RCC_GPIOB_CLK_ENABLE();
  __HAL_RCC_GPIOD_CLK_ENABLE();

  /*Configure GPIO pin Output Level */
  HAL_GPIO_WritePin(SPI1_SS1_GPIO_Port, SPI1_SS1_Pin, GPIO_PIN_SET);

  /*Configure GPIO pin Output Level */
  // SPI2_NSS (CS1) is active low CS pin - initialize to HIGH (inactive) to prevent interference
  HAL_GPIO_WritePin(SPI2_NSS_GPIO_Port, SPI2_NSS_Pin, GPIO_PIN_SET);
  HAL_GPIO_WritePin(GPIOB, SPI1_SS2_Pin|SPI1_SS3_Pin, GPIO_PIN_RESET);

  /*Configure GPIO pin Output Level */
  HAL_GPIO_WritePin(GPIOE, DRV_ENABLE_Pin|DRV_BRAKE_Pin|DRV_GP1_Pin|LED_CLIP_Pin
                          |LED_ERR_Pin, GPIO_PIN_RESET);

  /*Configure GPIO pin Output Level */
  // SPI2_SS2 and SPI2_SS3 are active low CS pins - initialize to HIGH (inactive) to prevent interference
  HAL_GPIO_WritePin(GPIOD, SPI2_SS2_Pin|SPI2_SS3_Pin, GPIO_PIN_SET);
  // SPI3_SS2 and SPI3_SS3 are active low CS pins - initialize to HIGH (inactive) to prevent interference
  HAL_GPIO_WritePin(GPIOD, SPI3_SS2_Pin|SPI3_SS3_Pin, GPIO_PIN_SET);
  HAL_GPIO_WritePin(GPIOD, CAN_S_Pin|GP1_Pin|LED_SYS_Pin, GPIO_PIN_RESET);

  /*Configure GPIO pin Output Level */
  // SPI3_SS1 is active low CS pin - initialize to HIGH (inactive) to prevent interference
  HAL_GPIO_WritePin(SPI3_SS1_GPIO_Port, SPI3_SS1_Pin, GPIO_PIN_SET);

  /*Configure GPIO pins : DIN7_Pin DIN6_Pin DIN5_Pin DIN4_Pin
                           DIN3_Pin */
  GPIO_InitStruct.Pin = DIN7_Pin|DIN6_Pin|DIN5_Pin|DIN4_Pin
                          |DIN3_Pin;
  GPIO_InitStruct.Mode = GPIO_MODE_INPUT;
  GPIO_InitStruct.Pull = GPIO_PULLUP;
  HAL_GPIO_Init(GPIOE, &GPIO_InitStruct);

  /*Configure GPIO pins : DIN2_Pin DIN1_Pin DIN0_Pin */
  GPIO_InitStruct.Pin = DIN2_Pin|DIN1_Pin|DIN0_Pin;
  GPIO_InitStruct.Mode = GPIO_MODE_INPUT;
  GPIO_InitStruct.Pull = GPIO_PULLUP;
  HAL_GPIO_Init(GPIOC, &GPIO_InitStruct);

  /*Configure GPIO pin : SPI1_SS1_Pin */
  GPIO_InitStruct.Pin = SPI1_SS1_Pin;
  GPIO_InitStruct.Mode = GPIO_MODE_OUTPUT_PP;
  GPIO_InitStruct.Pull = GPIO_NOPULL;
  GPIO_InitStruct.Speed = GPIO_SPEED_FREQ_VERY_HIGH;
  HAL_GPIO_Init(SPI1_SS1_GPIO_Port, &GPIO_InitStruct);

  /*Configure GPIO pins : SPI1_SS2_Pin SPI1_SS3_Pin SPI2_NSS_Pin */
  GPIO_InitStruct.Pin = SPI1_SS2_Pin|SPI1_SS3_Pin|SPI2_NSS_Pin;
  GPIO_InitStruct.Mode = GPIO_MODE_OUTPUT_PP;
  GPIO_InitStruct.Pull = GPIO_NOPULL;
  GPIO_InitStruct.Speed = GPIO_SPEED_FREQ_HIGH;
  HAL_GPIO_Init(GPIOB, &GPIO_InitStruct);

  /*Configure GPIO pin : BUTTON_A_Pin */
  GPIO_InitStruct.Pin = BUTTON_A_Pin;
  GPIO_InitStruct.Mode = GPIO_MODE_IT_RISING;
  GPIO_InitStruct.Pull = GPIO_PULLDOWN;
  HAL_GPIO_Init(BUTTON_A_GPIO_Port, &GPIO_InitStruct);

  /*Configure GPIO pin : DRV_ENABLE_Pin */
  GPIO_InitStruct.Pin = DRV_ENABLE_Pin;
  GPIO_InitStruct.Mode = GPIO_MODE_OUTPUT_PP;
  GPIO_InitStruct.Pull = GPIO_PULLDOWN;
  GPIO_InitStruct.Speed = GPIO_SPEED_FREQ_LOW;
  HAL_GPIO_Init(DRV_ENABLE_GPIO_Port, &GPIO_InitStruct);

  /*Configure GPIO pin : FLAG_Pin */
  GPIO_InitStruct.Pin = FLAG_Pin;
  GPIO_InitStruct.Mode = GPIO_MODE_IT_RISING;
  GPIO_InitStruct.Pull = GPIO_PULLDOWN;
  HAL_GPIO_Init(FLAG_GPIO_Port, &GPIO_InitStruct);

  /*Configure GPIO pin : DRV_BRAKE_Pin */
  GPIO_InitStruct.Pin = DRV_BRAKE_Pin;
  GPIO_InitStruct.Mode = GPIO_MODE_OUTPUT_PP;
  GPIO_InitStruct.Pull = GPIO_PULLDOWN;
  GPIO_InitStruct.Speed = GPIO_SPEED_FREQ_MEDIUM;
  HAL_GPIO_Init(DRV_BRAKE_GPIO_Port, &GPIO_InitStruct);

  /*Configure GPIO pins : DRV_GP1_Pin LED_CLIP_Pin LED_ERR_Pin */
  GPIO_InitStruct.Pin = DRV_GP1_Pin|LED_CLIP_Pin|LED_ERR_Pin;
  GPIO_InitStruct.Mode = GPIO_MODE_OUTPUT_PP;
  GPIO_InitStruct.Pull = GPIO_NOPULL;
  GPIO_InitStruct.Speed = GPIO_SPEED_FREQ_LOW;
  HAL_GPIO_Init(GPIOE, &GPIO_InitStruct);

  /*Configure GPIO pins : SPI2_SS2_Pin SPI2_SS3_Pin SPI3_SS2_Pin SPI3_SS3_Pin */
  GPIO_InitStruct.Pin = SPI2_SS2_Pin|SPI2_SS3_Pin|SPI3_SS2_Pin|SPI3_SS3_Pin;
  GPIO_InitStruct.Mode = GPIO_MODE_OUTPUT_PP;
  GPIO_InitStruct.Pull = GPIO_NOPULL;
  GPIO_InitStruct.Speed = GPIO_SPEED_FREQ_MEDIUM;
  HAL_GPIO_Init(GPIOD, &GPIO_InitStruct);

  /*Configure GPIO pin : ENCODER_Z_Pin */
  GPIO_InitStruct.Pin = ENCODER_Z_Pin;
  GPIO_InitStruct.Mode = GPIO_MODE_IT_FALLING;
  GPIO_InitStruct.Pull = GPIO_NOPULL;
  HAL_GPIO_Init(ENCODER_Z_GPIO_Port, &GPIO_InitStruct);

  /*Configure GPIO pin : ENCODER_Z_1_2_1_Pin */
  GPIO_InitStruct.Pin = ENCODER_Z_1_2_1_Pin;
  GPIO_InitStruct.Mode = GPIO_MODE_INPUT;
  GPIO_InitStruct.Pull = GPIO_NOPULL;
  HAL_GPIO_Init(ENCODER_Z_1_2_1_GPIO_Port, &GPIO_InitStruct);

  /*Configure GPIO pin : SPI3_SS1_Pin */
  GPIO_InitStruct.Pin = SPI3_SS1_Pin;
  GPIO_InitStruct.Mode = GPIO_MODE_OUTPUT_PP;
  GPIO_InitStruct.Pull = GPIO_NOPULL;
  GPIO_InitStruct.Speed = GPIO_SPEED_FREQ_HIGH;
  HAL_GPIO_Init(SPI3_SS1_GPIO_Port, &GPIO_InitStruct);

  /*Configure GPIO pins : CAN_S_Pin GP1_Pin LED_SYS_Pin */
  GPIO_InitStruct.Pin = CAN_S_Pin|GP1_Pin|LED_SYS_Pin;
  GPIO_InitStruct.Mode = GPIO_MODE_OUTPUT_PP;
  GPIO_InitStruct.Pull = GPIO_NOPULL;
  GPIO_InitStruct.Speed = GPIO_SPEED_FREQ_LOW;
  HAL_GPIO_Init(GPIOD, &GPIO_InitStruct);

  /*Configure GPIO pin : E_STOP_Pin */
  GPIO_InitStruct.Pin = E_STOP_Pin;
  GPIO_InitStruct.Mode = GPIO_MODE_IT_RISING_FALLING;
  GPIO_InitStruct.Pull = GPIO_PULLUP;
  HAL_GPIO_Init(E_STOP_GPIO_Port, &GPIO_InitStruct);

  /*Configure GPIO pins : GP2_Pin GP3_Pin */
  GPIO_InitStruct.Pin = GP2_Pin|GP3_Pin;
  GPIO_InitStruct.Mode = GPIO_MODE_INPUT;
  GPIO_InitStruct.Pull = GPIO_NOPULL;
  HAL_GPIO_Init(GPIOB, &GPIO_InitStruct);

  /* EXTI interrupt init*/
  HAL_NVIC_SetPriority(EXTI2_IRQn, 6, 0);
  HAL_NVIC_EnableIRQ(EXTI2_IRQn);

  HAL_NVIC_SetPriority(EXTI9_5_IRQn, 13, 0);
  HAL_NVIC_EnableIRQ(EXTI9_5_IRQn);

  HAL_NVIC_SetPriority(EXTI15_10_IRQn, 13, 0);
  HAL_NVIC_EnableIRQ(EXTI15_10_IRQn);

}

/* USER CODE BEGIN 4 */
void ExitDFU(void){
//	*((unsigned long *)0x2001FFF0) = 0xD00FBEAD; // invalidate flag and reset clean again
	//0x40024000 bkpsram
	*((unsigned long *)DFU_JUMP_MAGIC_ADR) = 0xD00FBEAD; // invalidate flag and reset clean again
	NVIC_SystemReset();
}

void RebootDFU(void) {
	//*((unsigned long *)0x2001FFF0) = 0xDEADBEEF; // ram end. see startup assembly for jumps
	// Para os timers PWM antes de entrar em DFU para evitar que o motor gire
	// TIM_PWM é definido como htim1 (TIM1)
	HAL_TIM_PWM_Stop(&htim1, TIM_CHANNEL_1);
	HAL_TIM_PWM_Stop(&htim1, TIM_CHANNEL_2);
	HAL_TIM_PWM_Stop(&htim1, TIM_CHANNEL_3);
	HAL_TIM_PWM_Stop(&htim1, TIM_CHANNEL_4);
	HAL_TIM_Base_Stop(&htim1);
	HAL_Delay(10); // Pequeno delay para garantir que os timers param

	*((unsigned long *)DFU_JUMP_MAGIC_ADR) = 0xDEADBEEF; // ram end. see startup assembly for jumps
	NVIC_SystemReset();
}
/* USER CODE END 4 */

__weak void StartDefaultTask(void *argument)
{
  /* USER CODE BEGIN 5 */
	HAL_GPIO_WritePin(LED_ERR_GPIO_Port, LED_ERR_Pin, GPIO_PIN_RESET);
	HAL_GPIO_WritePin(LED_CLIP_GPIO_Port, LED_CLIP_Pin, GPIO_PIN_RESET);
	HAL_GPIO_WritePin(LED_SYS_GPIO_Port, LED_SYS_Pin, GPIO_PIN_RESET);
  /* Infinite loop */
  for(;;)
  {
	  cppmain();
  }
  /* USER CODE END 5 */
}

void HAL_TIM_PeriodElapsedCallback(TIM_HandleTypeDef *htim)
{
  if (htim->Instance == TIM7) {
    HAL_IncTick();
  }
  /* USER CODE BEGIN Callback 1 */
  else{
	  HAL_TIM_PeriodElapsedCallback_CPP(htim);
  }
  /* USER CODE END Callback 1 */
}

void Error_Handler(void)
{
  /* USER CODE BEGIN Error_Handler_Debug */
  /* User can add his own implementation to report the HAL error return state */
	HAL_GPIO_WritePin(LED_ERR_GPIO_Port, LED_ERR_Pin, GPIO_PIN_RESET);
  /* USER CODE END Error_Handler_Debug */
}
